# STM32H730xxQ register map
File version: 1.0
Registers are 32-bit, read-write, reset 0x0 unless marked. A register's access mark holds for its fields unless they carry their own. Offsets are from the block's base; [hi:lo] are bit positions; {n}, {i} and the like mark numbered series.

## FDCAN1 — FD Controller Area Network
Base 0x4000A000
Same registers: FDCAN2 0x4000A400, FDCAN3 0x4000D400
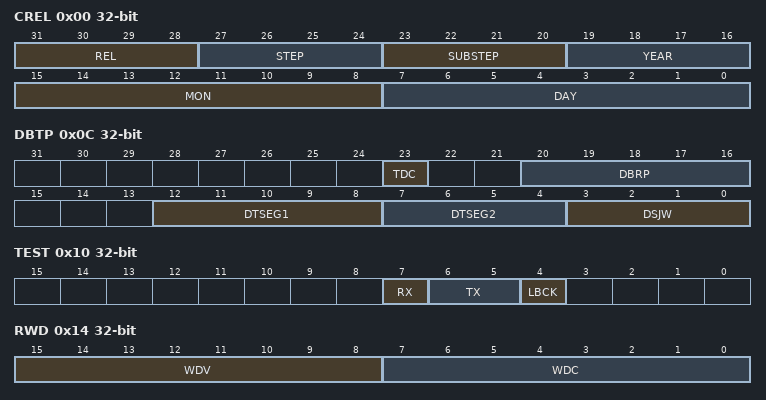
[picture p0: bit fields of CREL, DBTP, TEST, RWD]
0x00 CREL — FDCAN Core Release register
  [31:28] REL — Core release
  [27:24] STEP — Step of Core release
  [23:20] SUBSTEP — Sub-step of Core release
  [19:16] YEAR — Timestamp Year
  [15:8] MON — Timestamp Month
  [7:0] DAY — Timestamp Day
0x04 ENDN — FDCAN Endian register
  [31:0] ETV — Endianness Test Value
0x0C DBTP — FDCAN Data Bit Timing & Prescaler register
  [23] TDC — Transceiver Delay Compensation
  [20:16] DBRP — Data BIt Rate Prescaler
  [12:8] DTSEG1 — Data time segment before sample point
  [7:4] DTSEG2 — Data time segment after sample point
  [3:0] DSJW — Synchronization Jump Width
0x10 TEST — FDCAN Test register
  [7] RX — Receive Pin
  [6:5] TX — Control of Transmit Pin
  [4] LBCK — Loop Back mode
0x14 RWD — FDCAN RAM Watchdog register
  [15:8] WDV — Watchdog value
  [7:0] WDC — Watchdog configuration
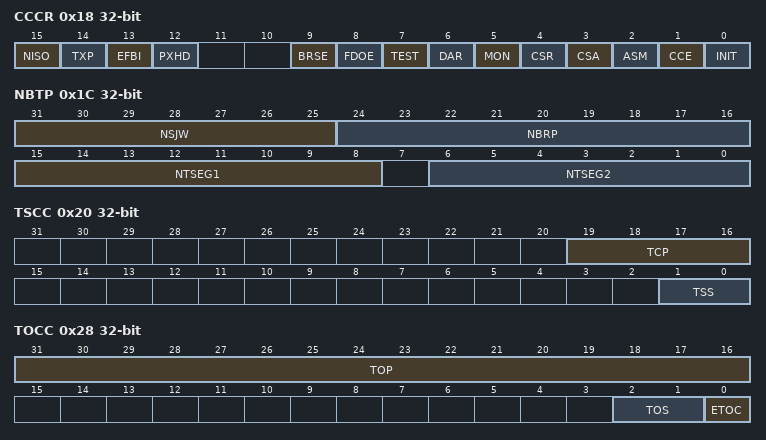
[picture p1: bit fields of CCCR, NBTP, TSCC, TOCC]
0x18 CCCR — FDCAN CC Control register
  [15] NISO — Non ISO Operation
  [14] TXP — Two CAN bit times Pause
  [13] EFBI — Edge Filtering during Bus Integration
  [12] PXHD — Protocol Exception Handling Disable
  [9] BRSE — FDCAN Bit Rate Switching
  [8] FDOE — FD Operation Enable
  [7] TEST — Test Mode Enable
  [6] DAR — Disable Automatic Retransmission
  [5] MON — Bus Monitoring Mode
  [4] CSR — Clock Stop Request
  [3] CSA — Clock Stop Acknowledge
  [2] ASM — ASM Restricted Operation Mode
  [1] CCE — Configuration Change Enable
  [0] INIT — Initialization
0x1C NBTP — FDCAN Nominal Bit Timing & Prescaler register
  [31:25] NSJW — Nominal (Re)Synchronization Jump Width
  [24:16] NBRP — Bit Rate Prescaler
  [15:8] NTSEG1 — Nominal Time segment before sample point
  [6:0] NTSEG2 — Nominal Time segment after sample point
0x20 TSCC — FDCAN Timestamp Counter Configuration register
  [19:16] TCP — Timestamp Counter Prescaler
  [1:0] TSS — Timestamp Select
0x24 TSCV — FDCAN Timestamp Counter Value register
  [15:0] TSC — Timestamp Counter
0x28 TOCC — FDCAN Timeout Counter Configuration register
  [31:16] TOP — Timeout Period
  [2:1] TOS — Timeout Select
  [0] ETOC — Enable Timeout Counter
0x2C TOCV — FDCAN Timeout Counter Value register
  [15:0] TOC — Timeout Counter
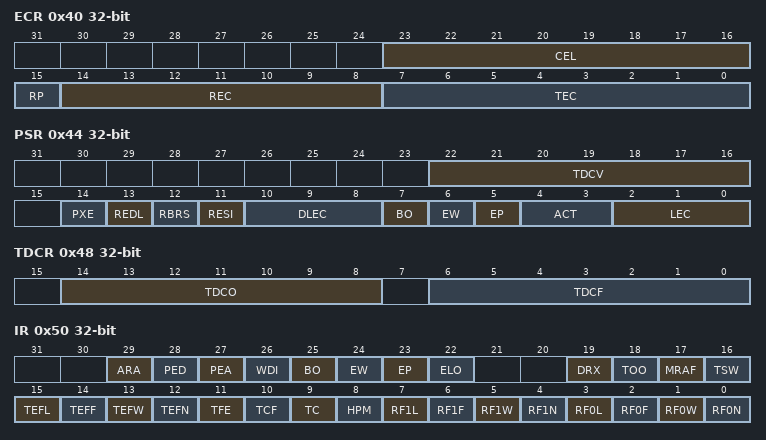
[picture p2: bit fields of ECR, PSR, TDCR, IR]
0x40 ECR — FDCAN Error Counter register
  [23:16] CEL — CAN Error Logging
  [15] RP — Receive Error Passive
  [14:8] REC — Receive Error Counter
  [7:0] TEC — Transmit Error Counter
0x44 PSR — FDCAN Protocol Status register
  [22:16] TDCV — Transmitter Delay Compensation Value
  [14] PXE — Protocol Exception Event
  [13] REDL — Received FDCAN Message
  [12] RBRS — BRS flag of last received FDCAN Message
  [11] RESI — ESI flag of last received FDCAN Message
  [10:8] DLEC — Data Last Error Code
  [7] BO — Bus_Off Status
  [6] EW — Warning Status
  [5] EP — Error Passive
  [4:3] ACT — Activity
  [2:0] LEC — Last Error Code
0x48 TDCR — FDCAN Transmitter Delay Compensation register
  [14:8] TDCO — Transmitter Delay Compensation Offset
  [6:0] TDCF — Transmitter Delay Compensation Filter
0x50 IR — FDCAN Interrupt register
  [29] ARA — Access to Reserved Address
  [28] PED — Protocol Error in Data Phase
  [27] PEA — Protocol Error in Arbitration Phase
  [26] WDI — Watchdog Interrupt
  [25] BO — Bus_Off Status
  [24] EW — Warning Status
  [23] EP — Error Passive
  [22] ELO — Error Logging Overflow
  [19] DRX — Message stored to Dedicated Rx Buffer
  [18] TOO — Timeout Occurred
  [17] MRAF — Message RAM Access Failure
  [16] TSW — Timestamp Wraparound
  [15] TEFL — Tx Event FIFO Element Lost
  [14] TEFF — Tx Event FIFO Full
  [13] TEFW — Tx Event FIFO Watermark Reached
  [12] TEFN — Tx Event FIFO New Entry
  [11] TFE — Tx FIFO Empty
  [10] TCF — Transmission Cancellation Finished
  [9] TC — Transmission Completed
  [8] HPM — High Priority Message
  [7] RF1L — Rx FIFO 1 Message Lost
  [6] RF1F — Rx FIFO 1 Full
  [5] RF1W — Rx FIFO 1 Watermark Reached
  [4] RF1N — Rx FIFO 1 New Message
  [3] RF0L — Rx FIFO 0 Message Lost
  [2] RF0F — Rx FIFO 0 Full
  [1] RF0W — Rx FIFO 0 Watermark Reached
  [0] RF0N — Rx FIFO 0 New Message
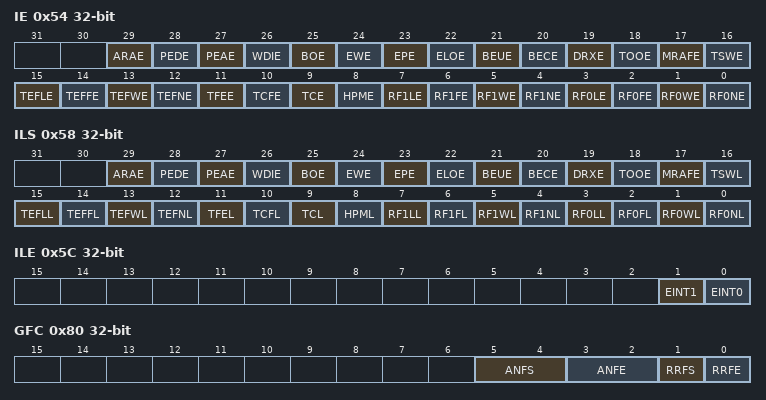
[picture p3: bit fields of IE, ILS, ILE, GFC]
0x54 IE — FDCAN Interrupt Enable register
  [29] ARAE — Access to Reserved Address Enable
  [28] PEDE — Protocol Error in Data Phase Enable
  [27] PEAE — Protocol Error in Arbitration Phase Enable
  [26] WDIE — Watchdog Interrupt Enable
  [25] BOE — Bus_Off Status Enable
  [24] EWE — Warning Status Enable
  [23] EPE — Error Passive Enable
  [22] ELOE — Error Logging Overflow Enable
  [21] BEUE — Bit Error Uncorrected Interrupt Enable
  [20] BECE — Bit Error Corrected Interrupt Enable
  [19] DRXE — Message stored to Dedicated Rx Buffer Enable
  [18] TOOE — Timeout Occurred Enable
  [17] MRAFE — Message RAM Access Failure Enable
  [16] TSWE — Timestamp Wraparound Enable
  [15] TEFLE — Tx Event FIFO Element Lost Enable
  [14] TEFFE — Tx Event FIFO Full Enable
  [13] TEFWE — Tx Event FIFO Watermark Reached Enable
  [12] TEFNE — Tx Event FIFO New Entry Enable
  [11] TFEE — Tx FIFO Empty Enable
  [10] TCFE — Transmission Cancellation Finished Enable
  [9] TCE — Transmission Completed Enable
  [8] HPME — High Priority Message Enable
  [7] RF1LE — Rx FIFO 1 Message Lost Enable
  [6] RF1FE — Rx FIFO 1 Full Enable
  [5] RF1WE — Rx FIFO 1 Watermark Reached Enable
  [4] RF1NE — Rx FIFO 1 New Message Enable
  [3] RF0LE — Rx FIFO 0 Message Lost Enable
  [2] RF0FE — Rx FIFO 0 Full Enable
  [1] RF0WE — Rx FIFO 0 Watermark Reached Enable
  [0] RF0NE — Rx FIFO 0 New Message Enable
0x58 ILS — FDCAN Interrupt Line Select register
  [29] ARAE — Access to Reserved Address Line
  [28] PEDE — Protocol Error in Data Phase Line
  [27] PEAE — Protocol Error in Arbitration Phase Line
  [26] WDIE — Watchdog Interrupt Line
  [25] BOE — Bus_Off Status Line
  [24] EWE — Warning Status Line
  [23] EPE — Error Passive Line
  [22] ELOE — Error Logging Overflow Line
  [21] BEUE — Bit Error Uncorrected Interrupt Line
  [20] BECE — Bit Error Corrected Interrupt Line
  [19] DRXE — Message stored to Dedicated Rx Buffer Line
  [18] TOOE — Timeout Occurred Line
  [17] MRAFE — Message RAM Access Failure Line
  [16] TSWL — Timestamp Wraparound Line
  [15] TEFLL — Tx Event FIFO Element Lost Line
  [14] TEFFL — Tx Event FIFO Full Line
  [13] TEFWL — Tx Event FIFO Watermark Reached Line
  [12] TEFNL — Tx Event FIFO New Entry Line
  [11] TFEL — Tx FIFO Empty Line
  [10] TCFL — Transmission Cancellation Finished Line
  [9] TCL — Transmission Completed Line
  [8] HPML — High Priority Message Line
  [7] RF1LL — Rx FIFO 1 Message Lost Line
  [6] RF1FL — Rx FIFO 1 Full Line
  [5] RF1WL — Rx FIFO 1 Watermark Reached Line
  [4] RF1NL — Rx FIFO 1 New Message Line
  [3] RF0LL — Rx FIFO 0 Message Lost Line
  [2] RF0FL — Rx FIFO 0 Full Line
  [1] RF0WL — Rx FIFO 0 Watermark Reached Line
  [0] RF0NL — Rx FIFO 0 New Message Line
0x5C ILE — FDCAN Interrupt Line Enable register
  [1] EINT1 — Enable Interrupt Line 1
  [0] EINT0 — Enable Interrupt Line 0
0x80 GFC — FDCAN Global Filter Configuration register
  [5:4] ANFS — Accept Non-matching Frames Standard
  [3:2] ANFE — Accept Non-matching Frames Extended
  [1] RRFS — Reject Remote Frames Standard
  [0] RRFE — Reject Remote Frames Extended
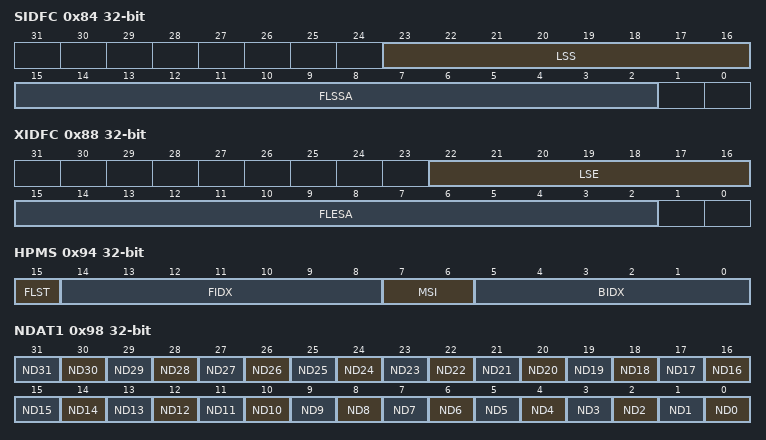
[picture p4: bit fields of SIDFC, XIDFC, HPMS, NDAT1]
0x84 SIDFC — FDCAN Standard ID Filter Configuration register
  [23:16] LSS — List Size Standard
  [15:2] FLSSA — Filter List Standard Start Address
0x88 XIDFC — FDCAN Extended ID Filter Configuration register
  [22:16] LSE — List Size Extended
  [15:2] FLESA — Filter List Standard Start Address
0x90 XIDAM — FDCAN Extended ID AND Mask register
  [28:0] EIDM — Extended ID Mask
0x94 HPMS — FDCAN High Priority Message Status register
  [15] FLST — Filter List
  [14:8] FIDX — Filter Index
  [7:6] MSI — Message Storage Indicator
  [5:0] BIDX — Buffer Index
0x98 NDAT1 — FDCAN New Data 1 register
  [n] ND{n} (n=0..31) — New Data flag of Rx Buffer {n}
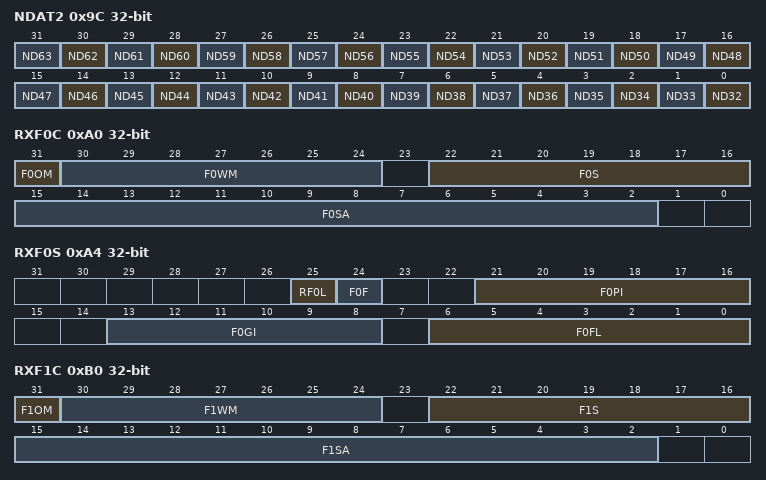
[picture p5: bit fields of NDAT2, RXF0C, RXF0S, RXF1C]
0x9C NDAT2 — FDCAN New Data 2 register
  [n-32] ND{n} (n=32..63) — New Data flag of Rx Buffer {n}
0xA0 RXF0C — FDCAN Rx FIFO 0 Configuration register
  [31] F0OM — FIFO 0 Operation Mode
  [30:24] F0WM — FIFO 0 Watermark
  [22:16] F0S — Number of Rx FIFO 0 elements
  [15:2] F0SA — Rx FIFO 0 Start Address
0xA4 RXF0S — FDCAN Rx FIFO 0 Status register
  [25] RF0L — Rx FIFO 0 Message Lost
  [24] F0F — Rx FIFO 0 Full
  [21:16] F0PI — Rx FIFO 0 Put Index
  [13:8] F0GI — Rx FIFO 0 Get Index
  [6:0] F0FL — Rx FIFO 0 Fill Level
0xA8 RXF0A — FDCAN Rx FIFO 0 Acknowledge register
  [5:0] F0AI — Rx FIFO 0 Acknowledge Index
0xAC RXBC — FDCAN Rx Buffer Configuration register
  [15:2] RBSA — Rx Buffer Start Address
0xB0 RXF1C — FDCAN Rx FIFO 1 Configuration register
  [31] F1OM — FIFO 1 Operation Mode
  [30:24] F1WM — Rx FIFO 1 Watermark
  [22:16] F1S — Number of Rx FIFO 1 elements
  [15:2] F1SA — Rx FIFO 1 Start Address
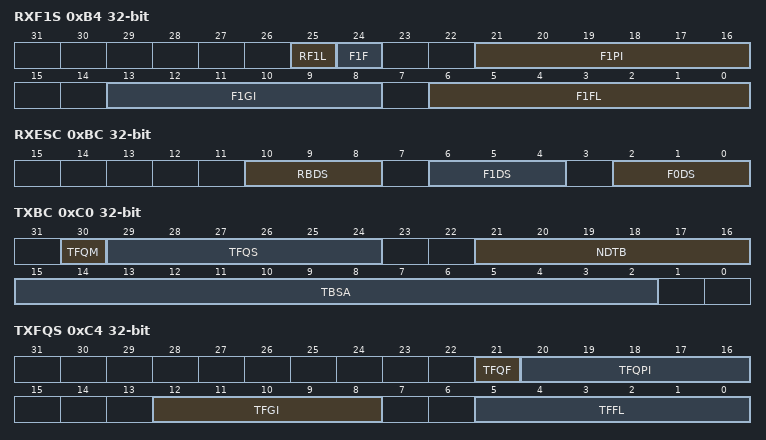
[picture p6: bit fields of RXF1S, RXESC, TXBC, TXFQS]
0xB4 RXF1S — FDCAN Rx FIFO 1 Status register
  [25] RF1L — Rx FIFO 1 Message Lost
  [24] F1F — Rx FIFO 1 Full
  [21:16] F1PI — Rx FIFO 1 Put Index
  [13:8] F1GI — Rx FIFO 1 Get Index
  [6:0] F1FL — Rx FIFO 1 Fill Level
0xB8 RXF1A — FDCAN Rx FIFO 1 Acknowledge register
  [5:0] F1AI — Rx FIFO 1 Acknowledge Index
0xBC RXESC — FDCAN Rx Buffer/FIFO Element Size Configuration register
  [10:8] RBDS — Rx Buffer Data Field Size
  [6:4] F1DS — Rx FIFO 0 Data Field Size
  [2:0] F0DS — Rx FIFO 1 Data Field Size
0xC0 TXBC — FDCAN Tx Buffer Configuration register
  [30] TFQM — Tx FIFO/Queue Mode
  [29:24] TFQS — Transmit FIFO/Queue Size
  [21:16] NDTB — Number of Dedicated Transmit Buffers
  [15:2] TBSA — Tx Buffers Start Address
0xC4 TXFQS — FDCAN Tx FIFO/Queue Status register
  [21] TFQF — Tx FIFO/Queue Full
  [20:16] TFQPI — Tx FIFO/Queue Put Index
  [12:8] TFGI — Tx FIFO Get Index
  [5:0] TFFL — Tx FIFO Free Level
0xC8 TXESC — FDCAN Tx Buffer Element Size Configuration register
  [2:0] TBDS — Tx Buffer Data Field Size
0xCC TXBRP — FDCAN Tx Buffer Request Pending register
  [31:0] TRP — Transmission Request Pending
0xD0 TXBAR — FDCAN Tx Buffer Add Request register
  [31:0] AR — Add Request
0xD4 TXBCR — FDCAN Tx Buffer Cancellation Request register
  [31:0] CR — Cancellation Request
0xD8 TXBTO — FDCAN Tx Buffer Transmission Occurred register
  [31:0] TO — Transmission Occurred
0xDC TXBCF — FDCAN Tx Buffer Cancellation Finished register
  [31:0] CF — Cancellation Finished
0xE0 TXBTIE — FDCAN Tx Buffer Transmission Interrupt Enable register
  [31:0] TIE — Transmission Interrupt Enable
0xE4 TXBCIE — FDCAN Tx Buffer Cancellation Finished Interrupt Enable register
  [31:0] CFIE — Cancellation Finished Interrupt Enable
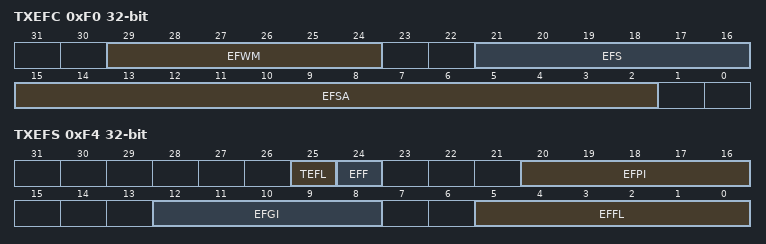
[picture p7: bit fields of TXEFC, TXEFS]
0xF0 TXEFC — FDCAN Tx Event FIFO Configuration register
  [29:24] EFWM — Event FIFO Watermark
  [21:16] EFS — Event FIFO Size
  [15:2] EFSA — Event FIFO Start Address
0xF4 TXEFS — FDCAN Tx Event FIFO Status register
  [25] TEFL — Tx Event FIFO Element Lost
  [24] EFF — Event FIFO Full
  [20:16] EFPI — Event FIFO Put Index
  [12:8] EFGI — Event FIFO Get Index
  [5:0] EFFL — Event FIFO Fill Level
0xF8 TXEFA — FDCAN Tx Event FIFO Acknowledge register
  [4:0] EFAI — Event FIFO Acknowledge Index
